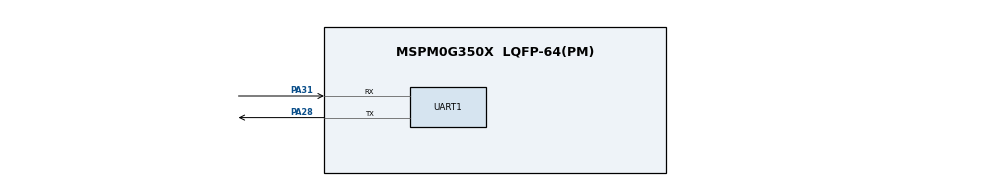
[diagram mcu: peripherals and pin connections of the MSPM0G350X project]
/**
 * @cliArgs --device "MSPM0G350X" --package "LQFP-64(PM)" --part "Default" --product "mspm0_sdk@2.01.00.03"
 * @versions {"tool":"1.20.0+3587"}
 */

/**
 * Import the modules used in this configuration.
 */
const ADC12         = scripting.addModule("/ti/driverlib/ADC12", {}, false);
const ADC121        = ADC12.addInstance();
const ADC122        = ADC12.addInstance();
const DMA           = scripting.addModule("/ti/driverlib/DMA");
const GPAMP         = scripting.addModule("/ti/driverlib/GPAMP", {}, false);
const GPAMP1        = GPAMP.addInstance();
const GPIO          = scripting.addModule("/ti/driverlib/GPIO", {}, false);
const GPIO1         = GPIO.addInstance();
const GPIO2         = GPIO.addInstance();
const OPA           = scripting.addModule("/ti/driverlib/OPA", {}, false);
const OPA1          = OPA.addInstance();
const SYSCTL        = scripting.addModule("/ti/driverlib/SYSCTL");
const TIMER         = scripting.addModule("/ti/driverlib/TIMER", {}, false);
const TIMER1        = TIMER.addInstance();
const TIMER2        = TIMER.addInstance();
const UART          = scripting.addModule("/ti/driverlib/UART", {}, false);
const UART1         = UART.addInstance();
const UART2         = UART.addInstance();
const ProjectConfig = scripting.addModule("/ti/project_config/ProjectConfig");

/**
 * Write custom configuration values to the imported modules.
 */
const divider9       = system.clockTree["UDIV"];
divider9.divideValue = 2;

const multiplier2         = system.clockTree["PLL_QDIV"];
multiplier2.multiplyValue = 5;

const mux8       = system.clockTree["HSCLKMUX"];
mux8.inputSelect = "HSCLKMUX_SYSPLL0";

ADC121.$name                          = "ADC12_0";
ADC121.subChanID                      = 1;
ADC121.configureDMA                   = true;
ADC121.trigSrc                        = "DL_ADC12_TRIG_SRC_EVENT";
ADC121.adcMem2chansel                 = "DL_ADC12_INPUT_CHAN_2";
ADC121.sampClkSrc                     = "DL_ADC12_CLOCK_ULPCLK";
ADC121.adcMem1chansel                 = "DL_ADC12_INPUT_CHAN_2";
ADC121.endAdd                         = 5;
ADC121.repeatMode                     = true;
ADC121.enableFIFO                     = true;
ADC121.adcMem0trig                    = "DL_ADC12_TRIGGER_MODE_TRIGGER_NEXT";
ADC121.enabledInterrupts              = ["DL_ADC12_INTERRUPT_DMA_DONE"];
ADC121.powerDownMode                  = "DL_ADC12_POWER_DOWN_MODE_MANUAL";
ADC121.sampleTime0                    = "0ns";
ADC121.adcMem1trig                    = "DL_ADC12_TRIGGER_MODE_TRIGGER_NEXT";
ADC121.sampCnt                        = 3;
ADC121.enabledDMATriggers             = ["DL_ADC12_DMA_MEM11_RESULT_LOADED","DL_ADC12_DMA_MEM5_RESULT_LOADED"];
ADC121.adcMem0chansel                 = "DL_ADC12_INPUT_CHAN_2";
ADC121.peripheral.$assign             = "ADC0";
ADC121.DMA_CHANNEL.$name              = "DMA_CH0";
ADC121.DMA_CHANNEL.transferSize       = 512;
ADC121.DMA_CHANNEL.addressMode        = "f2b";
ADC121.DMA_CHANNEL.peripheral.$assign = "DMA_CH0";
ADC121.adcPin2Config.$name            = "ti_driverlib_gpio_GPIOPinGeneric0";

ADC122.$name                          = "ADC12_1";
ADC122.subChanID                      = 2;
ADC122.sampClkSrc                     = "DL_ADC12_CLOCK_ULPCLK";
ADC122.trigSrc                        = "DL_ADC12_TRIG_SRC_EVENT";
ADC122.configureDMA                   = true;
ADC122.endAdd                         = 11;
ADC122.enableFIFO                     = true;
ADC122.repeatMode                     = true;
ADC122.adcMem0trig                    = "DL_ADC12_TRIGGER_MODE_TRIGGER_NEXT";
ADC122.powerDownMode                  = "DL_ADC12_POWER_DOWN_MODE_MANUAL";
ADC122.enabledInterrupts              = ["DL_ADC12_INTERRUPT_DMA_DONE"];
ADC122.sampleTime0                    = "0ns";
ADC122.adcMem1trig                    = "DL_ADC12_TRIGGER_MODE_TRIGGER_NEXT";
ADC122.sampCnt                        = 3;
ADC122.enabledDMATriggers             = ["DL_ADC12_DMA_MEM11_RESULT_LOADED","DL_ADC12_DMA_MEM5_RESULT_LOADED"];
ADC122.adcPin0Config.$name            = "ti_driverlib_gpio_GPIOPinGeneric3";
ADC122.DMA_CHANNEL.$name              = "DMA_CH1";
ADC122.DMA_CHANNEL.addressMode        = "f2b";
ADC122.DMA_CHANNEL.peripheral.$assign = "DMA_CH1";

const Board = scripting.addModule("/ti/driverlib/Board", {}, false);

DMA.enableBurst      = true;
DMA.enableRoundRobin = true;

GPAMP1.$name              = "GPAMP_0";
GPAMP1.cfgOutputPin       = "ENABLED";
GPAMP1.OutPinConfig.$name = "ti_driverlib_gpio_GPIOPinGeneric6";

GPIO1.$name                          = "GPIO_LEDS";
GPIO1.associatedPins[0].$name        = "USER_LED_1";
GPIO1.associatedPins[0].initialValue = "SET";
GPIO1.associatedPins[0].assignedPort = "PORTA";
GPIO1.associatedPins[0].assignedPin  = "0";

GPIO2.$name                          = "GPIO_AD9851";
GPIO2.associatedPins.create(4);
GPIO2.associatedPins[0].$name        = "D7";
GPIO2.associatedPins[0].assignedPin  = "8";
GPIO2.associatedPins[0].assignedPort = "PORTA";
GPIO2.associatedPins[1].$name        = "WCLK";
GPIO2.associatedPins[1].assignedPort = "PORTB";
GPIO2.associatedPins[1].assignedPin  = "18";
GPIO2.associatedPins[2].$name        = "FQUP";
GPIO2.associatedPins[2].assignedPort = "PORTB";
GPIO2.associatedPins[2].assignedPin  = "24";
GPIO2.associatedPins[3].$name        = "RST";
GPIO2.associatedPins[3].assignedPort = "PORTA";
GPIO2.associatedPins[3].assignedPin  = "24";

OPA1.$name = "OPA_0";

SYSCTL.forceDefaultClkConfig = true;
SYSCTL.clockTreeEn           = true;
SYSCTL.powerPolicy           = "STANDBY0";

TIMER1.$name                       = "TIMER_0";
TIMER1.timerMode                   = "PERIODIC";
TIMER1.event1PublisherChannel      = 1;
TIMER1.event1ControllerInterruptEn = ["ZERO_EVENT"];
TIMER1.event2PublisherChannel      = 2;
TIMER1.event2ControllerInterruptEn = ["ZERO_EVENT"];
TIMER1.timerPeriod                 = "1.63ms";
TIMER1.peripheral.$assign          = "TIMG0";

TIMER2.$name            = "TIMER_1";
TIMER2.timerClkPrescale = 256;
TIMER2.timerPeriod      = "3 us";

UART1.$name                    = "UART_0";
UART1.enabledInterrupts        = ["RX"];
UART1.interruptPriority        = "0";
UART1.targetBaudRate           = 115200;
UART1.peripheral.$assign       = "UART0";
UART1.peripheral.rxPin.$assign = "PA31";
UART1.peripheral.txPin.$assign = "PA28";
UART1.txPinConfig.$name        = "ti_driverlib_gpio_GPIOPinGeneric1";
UART1.rxPinConfig.$name        = "ti_driverlib_gpio_GPIOPinGeneric2";

UART2.$name             = "UART_1";
UART2.uartMode          = "RS485";
UART2.txPinConfig.$name = "ti_driverlib_gpio_GPIOPinGeneric4";
UART2.rxPinConfig.$name = "ti_driverlib_gpio_GPIOPinGeneric5";

ProjectConfig.genLibCMSIS = true;
ProjectConfig.genLibIQ    = true;

/**
 * Pinmux solution for unlocked pins/peripherals. This ensures that minor changes to the automatic solver in a future
 * version of the tool will not impact the pinmux you originally saw.  These lines can be completely deleted in order to
 * re-solve from scratch.
 */
ADC121.peripheral.adcPin2.$suggestSolution   = "PA25";
ADC122.peripheral.$suggestSolution           = "ADC1";
ADC122.peripheral.adcPin0.$suggestSolution   = "PA15";
Board.peripheral.$suggestSolution            = "DEBUGSS";
Board.peripheral.swclkPin.$suggestSolution   = "PA20";
Board.peripheral.swdioPin.$suggestSolution   = "PA19";
GPAMP1.peripheral.$suggestSolution           = "GPAMP";
GPAMP1.peripheral.OutPin.$suggestSolution    = "PA22";
GPIO1.associatedPins[0].pin.$suggestSolution = "PA0";
GPIO2.associatedPins[0].pin.$suggestSolution = "PA8";
GPIO2.associatedPins[1].pin.$suggestSolution = "PB18";
GPIO2.associatedPins[2].pin.$suggestSolution = "PB24";
GPIO2.associatedPins[3].pin.$suggestSolution = "PA24";
OPA1.peripheral.$suggestSolution             = "OPA0";
TIMER2.peripheral.$suggestSolution           = "TIMA0";
UART2.peripheral.$suggestSolution            = "UART1";
UART2.peripheral.rxPin.$suggestSolution      = "PA18";
UART2.peripheral.txPin.$suggestSolution      = "PA17";
